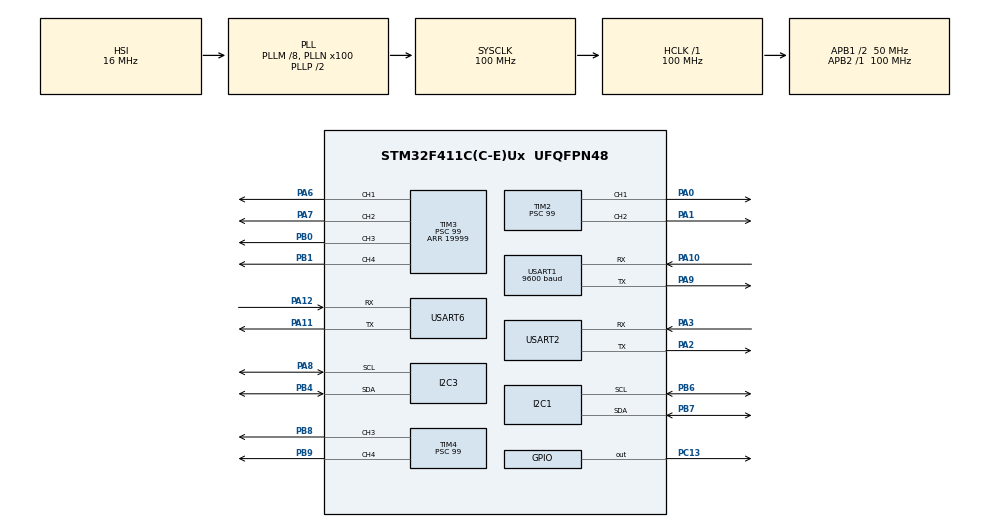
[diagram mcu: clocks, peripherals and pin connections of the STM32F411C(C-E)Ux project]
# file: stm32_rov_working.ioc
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Dma.I2C1_RX.2.Direction=DMA_PERIPH_TO_MEMORY
Dma.I2C1_RX.2.FIFOMode=DMA_FIFOMODE_DISABLE
Dma.I2C1_RX.2.Instance=DMA1_Stream0
Dma.I2C1_RX.2.MemDataAlignment=DMA_MDATAALIGN_BYTE
Dma.I2C1_RX.2.MemInc=DMA_MINC_ENABLE
Dma.I2C1_RX.2.Mode=DMA_NORMAL
Dma.I2C1_RX.2.PeriphDataAlignment=DMA_PDATAALIGN_BYTE
Dma.I2C1_RX.2.PeriphInc=DMA_PINC_DISABLE
Dma.I2C1_RX.2.Priority=DMA_PRIORITY_MEDIUM
Dma.I2C1_TX.3.Direction=DMA_MEMORY_TO_PERIPH
Dma.I2C1_TX.3.FIFOMode=DMA_FIFOMODE_DISABLE
Dma.I2C1_TX.3.Instance=DMA1_Stream1
Dma.I2C1_TX.3.MemDataAlignment=DMA_MDATAALIGN_BYTE
Dma.I2C1_TX.3.MemInc=DMA_MINC_ENABLE
Dma.I2C1_TX.3.Mode=DMA_NORMAL
Dma.I2C1_TX.3.PeriphDataAlignment=DMA_PDATAALIGN_BYTE
Dma.I2C1_TX.3.PeriphInc=DMA_PINC_DISABLE
Dma.I2C1_TX.3.Priority=DMA_PRIORITY_MEDIUM
Dma.I2C3_RX.0.Direction=DMA_PERIPH_TO_MEMORY
Dma.I2C3_RX.0.FIFOMode=DMA_FIFOMODE_DISABLE
Dma.I2C3_RX.0.Instance=DMA1_Stream2
Dma.I2C3_RX.0.MemDataAlignment=DMA_MDATAALIGN_BYTE
Dma.I2C3_RX.0.MemInc=DMA_MINC_ENABLE
Dma.I2C3_RX.0.Mode=DMA_NORMAL
Dma.I2C3_RX.0.PeriphDataAlignment=DMA_PDATAALIGN_BYTE
Dma.I2C3_RX.0.PeriphInc=DMA_PINC_DISABLE
Dma.I2C3_RX.0.Priority=DMA_PRIORITY_MEDIUM
Dma.I2C3_TX.1.Direction=DMA_MEMORY_TO_PERIPH
Dma.I2C3_TX.1.FIFOMode=DMA_FIFOMODE_DISABLE
Dma.I2C3_TX.1.Instance=DMA1_Stream4
Dma.I2C3_TX.1.MemDataAlignment=DMA_MDATAALIGN_BYTE
Dma.I2C3_TX.1.MemInc=DMA_MINC_ENABLE
Dma.I2C3_TX.1.Mode=DMA_NORMAL
Dma.I2C3_TX.1.PeriphDataAlignment=DMA_PDATAALIGN_BYTE
Dma.I2C3_TX.1.PeriphInc=DMA_PINC_DISABLE
Dma.I2C3_TX.1.Priority=DMA_PRIORITY_MEDIUM
Dma.Request0=I2C3_RX
Dma.Request1=I2C3_TX
Dma.Request2=I2C1_RX
Dma.Request3=I2C1_TX
FREERTOS.Tasks01=ledTask,8,128,StartLedTask,Default,NULL,Dynamic,NULL,NULL;uartTask,24,256,StartUartTask,Default,NULL,Dynamic,NULL,NULL
Mcu.Family=STM32F4
Mcu.Name=STM32F411C(C-E)Ux
Mcu.Package=UFQFPN48
NVIC.DMA1_Stream0_IRQn=true\:5\:0\:false\:false\:true\:true\:false\:true\:true
NVIC.DMA1_Stream1_IRQn=true\:5\:0\:false\:false\:true\:true\:false\:true\:true
NVIC.DMA1_Stream2_IRQn=true\:3\:0\:true\:false\:true\:true\:false\:true\:true
NVIC.DMA1_Stream4_IRQn=true\:4\:0\:true\:false\:true\:true\:false\:true\:true
NVIC.I2C1_ER_IRQn=true\:5\:0\:false\:false\:true\:true\:true\:true\:true
NVIC.I2C1_EV_IRQn=true\:5\:0\:false\:false\:true\:true\:true\:true\:true
NVIC.I2C3_ER_IRQn=true\:5\:0\:false\:false\:true\:true\:true\:true\:true
NVIC.I2C3_EV_IRQn=true\:5\:0\:false\:false\:true\:true\:true\:true\:true
NVIC.PriorityGroup=NVIC_PRIORITYGROUP_4
NVIC.TIM5_IRQn=true\:15\:0\:false\:false\:true\:false\:false\:true\:true
NVIC.TimeBase=TIM5_IRQn
NVIC.TimeBaseIP=TIM5
NVIC.USART1_IRQn=true\:5\:0\:false\:false\:true\:true\:true\:true\:true
NVIC.USART2_IRQn=true\:5\:0\:true\:false\:true\:true\:true\:true\:true
NVIC.USART6_IRQn=true\:5\:0\:true\:false\:true\:true\:true\:true\:true
PA0-WKUP.Signal=S_TIM2_CH1_ETR
PA1.Signal=S_TIM2_CH2
PA10.Mode=Asynchronous
PA10.Signal=USART1_RX
PA11.Mode=Asynchronous
PA11.Signal=USART6_TX
PA12.Mode=Asynchronous
PA12.Signal=USART6_RX
PA13.Mode=Serial_Wire
PA13.Signal=SYS_JTMS-SWDIO
PA14.Mode=Serial_Wire
PA14.Signal=SYS_JTCK-SWCLK
PA2.Mode=Asynchronous
PA2.Signal=USART2_TX
PA3.Mode=Asynchronous
PA3.Signal=USART2_RX
PA6.Signal=S_TIM3_CH1
PA7.Signal=S_TIM3_CH2
PA8.GPIO_Pu=GPIO_PULLUP
PA8.Mode=I2C
PA8.Signal=I2C3_SCL
PA9.Mode=Asynchronous
PA9.Signal=USART1_TX
PB0.Signal=S_TIM3_CH3
PB1.Signal=S_TIM3_CH4
PB4.GPIO_Pu=GPIO_PULLUP
PB4.Mode=I2C
PB4.Signal=I2C3_SDA
PB6.Mode=I2C
PB6.Signal=I2C1_SCL
PB7.Mode=I2C
PB7.Signal=I2C1_SDA
PB8.Signal=S_TIM4_CH3
PB9.Signal=S_TIM4_CH4
PC13-ANTI_TAMP.Signal=GPIO_Output
PH0\ -\ OSC_IN.Mode=HSE-External-Oscillator
PH0\ -\ OSC_IN.Signal=RCC_OSC_IN
PH1\ -\ OSC_OUT.Mode=HSE-External-Oscillator
PH1\ -\ OSC_OUT.Signal=RCC_OSC_OUT
ProjectManager.HeapSize=0x200
ProjectManager.StackSize=0x400
ProjectManager.TargetToolchain=STM32CubeIDE
RCC.48MHZClocksFreq_Value=28571428.57142857
RCC.AHBFreq_Value=100000000
RCC.APB1CLKDivider=RCC_HCLK_DIV2
RCC.APB1Freq_Value=50000000
RCC.APB1TimFreq_Value=100000000
RCC.APB2Freq_Value=100000000
RCC.APB2TimFreq_Value=100000000
RCC.CortexFreq_Value=100000000
RCC.HCLKFreq_Value=100000000
RCC.HSE_VALUE=25000000
RCC.HSI_VALUE=16000000
RCC.LSE_VALUE=32768
RCC.PLLM=8
RCC.PLLN=100
RCC.PLLQ=7
RCC.SYSCLKFreq_VALUE=100000000
RCC.SYSCLKSource=RCC_SYSCLKSOURCE_PLLCLK
RCC.VCOOutputFreq_Value=200000000
SH.S_TIM2_CH1_ETR.0=TIM2_CH1,PWM Generation1 CH1
SH.S_TIM2_CH2.0=TIM2_CH2,PWM Generation2 CH2
SH.S_TIM3_CH1.0=TIM3_CH1,PWM Generation1 CH1
SH.S_TIM3_CH2.0=TIM3_CH2,PWM Generation2 CH2
SH.S_TIM3_CH3.0=TIM3_CH3,PWM Generation3 CH3
SH.S_TIM3_CH4.0=TIM3_CH4,PWM Generation4 CH4
SH.S_TIM4_CH3.0=TIM4_CH3,PWM Generation3 CH3
SH.S_TIM4_CH4.0=TIM4_CH4,PWM Generation4 CH4
TIM2.AutoReloadPreload=TIM_AUTORELOAD_PRELOAD_ENABLE
TIM2.Channel-PWM\ Generation1\ CH1=TIM_CHANNEL_1
TIM2.Channel-PWM\ Generation2\ CH2=TIM_CHANNEL_2
TIM2.Period=19999
TIM2.Prescaler=99
TIM3.AutoReloadPreload=TIM_AUTORELOAD_PRELOAD_ENABLE
TIM3.Channel-PWM\ Generation1\ CH1=TIM_CHANNEL_1
TIM3.Channel-PWM\ Generation2\ CH2=TIM_CHANNEL_2
TIM3.Channel-PWM\ Generation3\ CH3=TIM_CHANNEL_3
TIM3.Channel-PWM\ Generation4\ CH4=TIM_CHANNEL_4
TIM3.Period=19999
TIM3.Prescaler=99
TIM4.AutoReloadPreload=TIM_AUTORELOAD_PRELOAD_ENABLE
TIM4.Channel-PWM\ Generation3\ CH3=TIM_CHANNEL_3
TIM4.Channel-PWM\ Generation4\ CH4=TIM_CHANNEL_4
TIM4.Period=19999
TIM4.Prescaler=99
USART1.BaudRate=9600
USART1.Parity=PARITY_EVEN
USART1.VirtualMode=VM_ASYNC
USART1.WordLength=WORDLENGTH_9B
USART2.VirtualMode=VM_ASYNC
USART6.VirtualMode=VM_ASYNC
VP_FREERTOS_VS_CMSIS_V2.Mode=CMSIS_V2
VP_SYS_VS_tim5.Mode=TIM5
VP_TIM2_VS_ClockSourceINT.Mode=Internal
VP_TIM3_VS_ClockSourceINT.Mode=Internal
VP_TIM4_VS_ClockSourceINT.Mode=Internal
board=custom

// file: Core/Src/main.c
/* USER CODE BEGIN Header */
/**
  ******************************************************************************
  * @file           : main.c
  * @brief          : Main program body
  ******************************************************************************
  * @attention
  *
  * Copyright (c) 2026 STMicroelectronics.
  * All rights reserved.
  *
  * This software is licensed under terms that can be found in the LICENSE file
  * in the root directory of this software component.
  * If no LICENSE file comes with this software, it is provided AS-IS.
  *
  ******************************************************************************
  */
/* USER CODE END Header */
#include "main.h"
#include "cmsis_os.h"
#include "dma.h"
#include "i2c.h"
#include "tim.h"
#include "usart.h"
#include "gpio.h"

/* USER CODE BEGIN Includes */
#include "app_mode.h"
#include "ms5837_dma.h"
#include "PID.h"
#include "mpu6050.h"
#include <string.h>

/* USER CODE END Includes */

/* USER CODE BEGIN PTD */
MS5837_t depth_sensor;            // Sensor instance
PID_t pid_depth;
PID_t pid_pitch;
PID_t pid_roll;
MPU6050_t mpu6050;                // MPU6050 IMU instance

/* USER CODE END PTD */

/* USER CODE BEGIN PD */

/* Task 1 bench mode: no sensors, ESC PWM, or ROV control are started. */
#define COMM_TEST_MODE  1

// ---- VERTICAL MOTORS (depth control) ----
//   V_FL = Front Left  = TIM4 CH3 = PB8
//   V_FR = Front Right = TIM4 CH4 = PB9
//   V_RL = Rear Left   = TIM2 CH1 = PA0
//   V_RR = Rear Right  = TIM3 CH4 = PB1
#define MOTOR_V_FL  TIM_CHANNEL_3   // htim4 CH3, PB8
#define MOTOR_V_FR  TIM_CHANNEL_4   // htim4 CH4, PB9
#define MOTOR_V_RL  TIM_CHANNEL_1   // htim2 CH1, PA0
#define MOTOR_V_RR  TIM_CHANNEL_4   // htim3 CH4, PB1

// ---- HORIZONTAL MOTORS ----
//   O_FL = Front Left  = TIM3 CH1 = PA6
//   O_FR = Front Right = TIM2 CH2 = PA1
//   O_RL = Rear Left   = TIM3 CH2 = PA7
//   O_RR = Rear Right  = TIM3 CH3 = PB0
#define MOTOR_O_FL  TIM_CHANNEL_1   // htim3 CH1, PA6
#define MOTOR_O_FR  TIM_CHANNEL_2   // htim2 CH2, PA1
#define MOTOR_O_RL  TIM_CHANNEL_2   // htim3 CH2, PA7
#define MOTOR_O_RR  TIM_CHANNEL_3   // htim3 CH3, PB0

/* USER CODE END PD */

/* USER CODE BEGIN PV */
float pressure, temp, depth;
float err_depth, out_depth, err_pitch , out_pitch, err_roll, out_roll;
int time = 0;
float target_depth = 0.1f;
float current_depth = 0.0f;
//float target_pitch = 4.7f;   // target pitch angle in degrees (0 = level)
//float target_roll = -2.3f;      // target roll angle in degrees (0 = level)

// --- Horizontal (omnidirectional) movement ---
// forward_input: -500 to +500  (positive = forward, negative = backward)
//int forward_input = 150;

// --- Depth stabilization gate for horizontal motors ---
// Horizontal thrust is DISABLED until depth stabilizes.
// Depth must stay within DEPTH_STABLE_TOL of target for
// DEPTH_STABLE_COUNT consecutive loop iterations.
#define DEPTH_STABLE_TOL    0.05f   // metres – how close is "stable"
#define DEPTH_STABLE_COUNT  50      // iterations (~1 s at 50 Hz loop)
int  stable_counter = 0;            // consecutive-in-range counter
int  depth_stable   = 0;            // 1 = stable, horizontal enabled
/* USER CODE END PV */

void SystemClock_Config(void);
void MX_FREERTOS_Init(void);
/* USER CODE BEGIN PFP */

void CommTest_UART_RxCpltCallback(void);
void CommTest_UART_TxCpltCallback(void);

/* USER CODE END PFP */

/* USER CODE BEGIN 0 */

int system_armed = 0;      // Safety Flag

/* HC-05 update command receiver. USART1 is PA9 (TX) / PA10 (RX). */
static uint8_t update_rx_byte;
static char update_command[16];
static uint8_t update_command_index;

/* Stop every ESC signal before handing control to the STM32 ROM bootloader. */
void ROV_ForceNeutralOutputs(void)
{
    system_armed = 0;

    __HAL_TIM_SET_COMPARE(&htim2, TIM_CHANNEL_1, 1500);
    __HAL_TIM_SET_COMPARE(&htim2, TIM_CHANNEL_2, 1500);
    __HAL_TIM_SET_COMPARE(&htim3, TIM_CHANNEL_1, 1500);
    __HAL_TIM_SET_COMPARE(&htim3, TIM_CHANNEL_2, 1500);
    __HAL_TIM_SET_COMPARE(&htim3, TIM_CHANNEL_3, 1500);
    __HAL_TIM_SET_COMPARE(&htim3, TIM_CHANNEL_4, 1500);
    __HAL_TIM_SET_COMPARE(&htim4, TIM_CHANNEL_3, 1500);
    __HAL_TIM_SET_COMPARE(&htim4, TIM_CHANNEL_4, 1500);
}

static void ROV_StopMotors(void)
{
    GPIO_InitTypeDef gpio = {0};

    ROV_ForceNeutralOutputs();

    HAL_TIM_PWM_Stop(&htim2, TIM_CHANNEL_1);
    HAL_TIM_PWM_Stop(&htim2, TIM_CHANNEL_2);
    HAL_TIM_PWM_Stop(&htim3, TIM_CHANNEL_1);
    HAL_TIM_PWM_Stop(&htim3, TIM_CHANNEL_2);
    HAL_TIM_PWM_Stop(&htim3, TIM_CHANNEL_3);
    HAL_TIM_PWM_Stop(&htim3, TIM_CHANNEL_4);
    HAL_TIM_PWM_Stop(&htim4, TIM_CHANNEL_3);
    HAL_TIM_PWM_Stop(&htim4, TIM_CHANNEL_4);

    /* Sensor-only safety lock: ESC signal pins are ordinary low outputs,
       not timer alternate-function outputs. */
    HAL_GPIO_WritePin(GPIOA,
                      GPIO_PIN_0 | GPIO_PIN_1 | GPIO_PIN_6 | GPIO_PIN_7,
                      GPIO_PIN_RESET);
    HAL_GPIO_WritePin(GPIOB,
                      GPIO_PIN_0 | GPIO_PIN_1 | GPIO_PIN_8 | GPIO_PIN_9,
                      GPIO_PIN_RESET);

    gpio.Mode = GPIO_MODE_OUTPUT_PP;
    gpio.Pull = GPIO_PULLDOWN;
    gpio.Speed = GPIO_SPEED_FREQ_LOW;

    gpio.Pin = GPIO_PIN_0 | GPIO_PIN_1 | GPIO_PIN_6 | GPIO_PIN_7;
    HAL_GPIO_Init(GPIOA, &gpio);

    gpio.Pin = GPIO_PIN_0 | GPIO_PIN_1 | GPIO_PIN_8 | GPIO_PIN_9;
    HAL_GPIO_Init(GPIOB, &gpio);
}

/* Jump to the factory STM32 USART bootloader at system-memory address. */
static void JumpToSystemBootloader(void)
{
    const uint32_t bootloader_base = 0x1FFF0000UL; /* STM32F411 system memory */
    uint32_t boot_msp;
    uint32_t boot_reset_handler;

    ROV_StopMotors();
    HAL_UART_DeInit(&huart1);

    /* The watchdog returns to the ROV firmware if a flashing session aborts. */
    IWDG->KR  = 0xCCCC;
    IWDG->KR  = 0x5555;
    IWDG->PR  = 0x03;
    IWDG->RLR = 0xAA0;
    IWDG->KR  = 0xAAAA;

    SysTick->CTRL = 0;
    SysTick->LOAD = 0;
    SysTick->VAL  = 0;

    RCC->APB2RSTR |= RCC_APB2RSTR_USART1RST;
    RCC->APB2RSTR &= ~RCC_APB2RSTR_USART1RST;

    RCC->CR |= RCC_CR_HSION;
    while ((RCC->CR & RCC_CR_HSIRDY) == 0) { }
    RCC->CFGR &= ~RCC_CFGR_SW;
    while ((RCC->CFGR & RCC_CFGR_SWS_Msk) != 0) { }
    RCC->CR &= ~(RCC_CR_PLLON | RCC_CR_HSEON);
    RCC->CFGR = 0;

    __disable_irq();
    for (uint32_t i = 0; i < 8; i++) {
        NVIC->ICER[i] = 0xFFFFFFFFUL;
        NVIC->ICPR[i] = 0xFFFFFFFFUL;
    }

    for (volatile uint32_t i = 0; i < 16000; i++) { }

    boot_msp = *(volatile uint32_t *)bootloader_base;
    boot_reset_handler = *(volatile uint32_t *)(bootloader_base + 4U);
    SCB->VTOR = bootloader_base;
    __DSB();
    __ISB();
    __set_MSP(boot_msp);
    ((void (*)(void))boot_reset_handler)();

    while (1) { }
}

void Set_Motor_PWM(TIM_HandleTypeDef *htim, uint32_t channel, int pwm) {
    __HAL_TIM_SET_COMPARE(htim, channel, pwm);
}
/* USER CODE END 0 */

int main(void)
{

  /* MCU Configuration--------------------------------------------------------*/

  /* Reset of all peripherals, Initializes the Flash interface and the Systick. */
  HAL_Init();

  /* Configure the system clock */
  SystemClock_Config();

  /* Initialize all configured peripherals */
  MX_GPIO_Init();
  MX_DMA_Init();
  MX_TIM2_Init();
  MX_TIM3_Init();
  MX_TIM4_Init();
  MX_I2C3_Init();
  MX_I2C1_Init();
  MX_USART1_UART_Init();
  MX_USART2_UART_Init();
  MX_USART6_UART_Init();
  /* USER CODE BEGIN 2 */
#if (!APP_MOTOR_OUTPUTS_ENABLED) && (!APP_MOTOR_NEUTRAL_TEST)
  ROV_StopMotors();
#endif

  /* Keep this in a USER CODE section: CubeMX regeneration will not remove it. */
  if (HAL_UART_Receive_IT(&huart1, &update_rx_byte, 1) != HAL_OK)
  {
    Error_Handler();
  }
  HAL_GPIO_WritePin(GPIOC, GPIO_PIN_13, 1);
#if !COMM_TEST_MODE
  if (MS5837_Init(&depth_sensor, &hi2c3, MS5837_OSR_4096) != MS5837_OK) {
    Error_Handler();
    } // Initalize the depth sensor

    /***********************************************************************
     * !!! IMPORTANT – IMU I2C BUS SELECTION !!!
     * The IMU (MPU6050) is initialised below using hi2c1.
     * Make sure this matches the actual I2C peripheral the IMU is wired to.
     * If your IMU is on I2C2, change &hi2c1 → &hi2c2 (and declare hi2c2).
     * If your IMU is on I2C3, change &hi2c1 → &hi2c3.
//     ***********************************************************************/
//    if (MPU6050_Init(&mpu6050, &hi2c1, MPU6050_ADDR) != HAL_OK) {
//        // IMU init failed – optionally handle error
//    }

  	PIDSourceInit(&err_depth, &out_depth, &pid_depth);
  	PIDGainInit(0.02, 1.0, 1.0, 100.0, 0.2, 0.0, 0.0, 10.0, &pid_depth);
    PIDDelayInit(&pid_depth); // initialize depth PID
//
//    // Initialize pitch PID (tune gains as needed)
//    PIDSourceInit(&err_pitch, &out_pitch, &pid_pitch);
//    PIDGainInit(0.02, 1.0, 1.0, 200.0, 0.3, 0.0, 0.0, 10.0, &pid_pitch);
//    PIDDelayInit(&pid_pitch); // initialize pitch PID
//
//    PIDSourceInit(&err_roll, &out_roll, &pid_roll);
//    PIDGainInit(0.02, 1.0, 1.0, 200.0, 0.3, 0.0, 0.0, 10.0, &pid_roll);
//    PIDDelayInit(&pid_roll); // initialize roll PID

    HAL_TIM_PWM_Start(&htim2, TIM_CHANNEL_1); // PA0
//    HAL_TIM_PWM_Start(&htim2, TIM_CHANNEL_2); // PA1
//    HAL_TIM_PWM_Start(&htim3, TIM_CHANNEL_1); // PA6
//    HAL_TIM_PWM_Start(&htim3, TIM_CHANNEL_2); // PA7
//    HAL_TIM_PWM_Start(&htim3, TIM_CHANNEL_3); // PB0
    HAL_TIM_PWM_Start(&htim3, TIM_CHANNEL_4); // PB1
    HAL_TIM_PWM_Start(&htim4, TIM_CHANNEL_3); // PB0
    HAL_TIM_PWM_Start(&htim4, TIM_CHANNEL_4); // PB1
#endif

    HAL_GPIO_WritePin(GPIOC, GPIO_PIN_13, 0);

  /* USER CODE END 2 */

  /* Init scheduler */
  osKernelInitialize();  /* Call init function for freertos objects (in cmsis_os2.c) */
  MX_FREERTOS_Init();

  /* Start scheduler */
  osKernelStart();

  /* We should never get here as control is now taken by the scheduler */

  /* Infinite loop */
  while (1)
  {

    /* USER CODE BEGIN 3 */

		  // --- IMU reading (DMA-based MPU6050) ---
//		  MPU6050_ReadAll_DMA(&mpu6050);   // kick off non-blocking DMA read
//		  MPU6050_ProcessData(&mpu6050);   // process if DMA data is ready

		  static uint32_t last_time = 0;
		  	    if ((HAL_GetTick() - last_time) >= 100) {
		  	        if (MS5837_GetState(&depth_sensor) == MS5837_STATE_IDLE) {
		  	            MS5837_StartReading(&depth_sensor);
		  	            last_time = HAL_GetTick();
		  	        }
		  	    }

		  	    MS5837_Process(&depth_sensor);

		  	    if (MS5837_IsDataReady(&depth_sensor)) {
		  	         pressure = MS5837_GetPressure(&depth_sensor);
		  	         temp = MS5837_GetTemperature(&depth_sensor);
		  	         depth = MS5837_GetDepth(&depth_sensor);
		  	    	 current_depth = MS5837_GetDepth(&depth_sensor);
		  	    }
		  	  if (system_armed)
		  	  	    {

//		  	  	    	err_depth = target_depth - current_depth;
//		  	  	    	PID(&pid_depth);
		  	  	    // ============================
		  	  	    // DEPTH PID CONTROL ONLY
		  	  	    // ============================

		  	  	    // Calculate depth error
		  	  	    err_depth = target_depth - current_depth;

		  	  	    // PID calculation
		  	  	    PID(&pid_depth);

		  	  	    // Convert PID output to PWM correction
		  	  	    int u_depth = (int)(out_depth * 2);

		  	  	    // Dead zone compensation
		  	  	    if(u_depth > 0)
		  	  	    {
		  	  	        u_depth += 80;
		  	  	    }
		  	  	    else if(u_depth < 0)
		  	  	    {
		  	  	        u_depth -= 80;
		  	  	    }

		  	  	    // Limit PID output
		  	  	    if(u_depth > 300)
		  	  	        u_depth = 300;

		  	  	    if(u_depth < -300)
		  	  	        u_depth = -300;

		  	  	    int base = 1500;

		  	  	    // ============================
		  	  	    // VERTICAL MOTOR MIXING
		  	  	    // DEPTH ONLY
		  	  	    // ============================

		  	  	    int pwm_FL = base + u_depth;
		  	  	    int pwm_FR = base + u_depth;
		  	  	    int pwm_RL = base + u_depth;
		  	  	    int pwm_RR = base + u_depth;

		  	  	    // PWM safety limit
		  	  	    if(pwm_FL > 1800) pwm_FL = 1800;
		  	  	    if(pwm_FL < 1200) pwm_FL = 1200;

		  	  	    if(pwm_FR > 1800) pwm_FR = 1800;
		  	  	    if(pwm_FR < 1200) pwm_FR = 1200;

		  	  	    if(pwm_RL > 1800) pwm_RL = 1800;
		  	  	    if(pwm_RL < 1200) pwm_RL = 1200;

		  	  	    if(pwm_RR > 1800) pwm_RR = 1800;
		  	  	    if(pwm_RR < 1200) pwm_RR = 1200;

		  	  	    // Send PWM
		  	  	    __HAL_TIM_SET_COMPARE(&htim4, TIM_CHANNEL_3, pwm_FL);
		  	  	    __HAL_TIM_SET_COMPARE(&htim4, TIM_CHANNEL_4, pwm_FR);

		  	  	    __HAL_TIM_SET_COMPARE(&htim2, TIM_CHANNEL_1, pwm_RL);

		  	  	    __HAL_TIM_SET_COMPARE(&htim3, TIM_CHANNEL_4, pwm_RR);

//		  	  	    	// --- Pitch PID (uses MPU6050 pitch) ---
//		  	  	    	err_pitch = target_pitch - MPU6050_GetPitch(&mpu6050);
//		  	  	    	PID(&pid_pitch);
//
//		  	  	    	// --- Roll PID (uses MPU6050 roll) ---
//		  	  	    	err_roll = target_roll - MPU6050_GetRoll(&mpu6050);
//		  	  	    	PID(&pid_roll);

//		  	  		      int base = 1500;
//
//		  	  		      // --- Depth PID output ---
//		  	  		      int u_depth = 200;
//
//		  	  		      //   Dead zone compensation
//		  	  		      if (u_depth > 0) u_depth += 100;
//		  	  		      if (u_depth < 0) u_depth -= 100;
//		  	  		      // Limit
//		  	  		      if (u_depth > 300) u_depth = 300;
//		  	  		      if (u_depth < -300) u_depth = -300;

//		  	  		      // --- Pitch PID output ---
//		  	  		      int u_pitch = (int)(out_pitch * 2);
//
//		  	  		      // Pitch dead zone compensation
//		  	  		      if (u_pitch > 0) u_pitch += 50;
//		  	  		      if (u_pitch < 0) u_pitch -= 50;
//		  	  		      // Pitch limit
//		  	  		      if (u_pitch > 200) u_pitch = 200;
//		  	  		      if (u_pitch < -200) u_pitch = -200;
//
//                           // ----- roll PID output -----
//                          int u_roll = (int)(out_roll * 2);
//                          // Roll dead zone compensation
//                          if (u_roll > 0) u_roll += 50;
//                          if (u_roll < 0) u_roll -= 50;
//                               // Roll limit
//                          if (u_roll > 200) u_roll = 200;
//                          if (u_roll < -200) u_roll = -200;

		  	  		      /***********************************************************************
		  	  		       * VERTICAL MOTOR MIXING: depth + pitch + roll
		  	  		       *
		  	  		       *   u_depth : common-mode (all motors together for heave)
		  	  		       *   u_pitch : differential  (front vs rear for pitch torque)
		  	  		       *    u_roll  : differential  (left vs right for roll torque)
		  	  		       *   Positive pitch error = nose up  → push front down, rear up
		  	  		       *     Front motors: subtract u_pitch (more thrust downward)
		  	  		       *     Rear  motors: add u_pitch      (less thrust downward)
		  	  		       *
		  	  		       * !!! FIRST TEST: If pitch correction is reversed, swap the
		  	  		       *     +/- signs on u_pitch below. !!!
		  	  		       ***********************************************************************/
		  	  		      // FR (Front Right)

//		  	  		      int pwm_FR = base + u_depth ;
//
//		  	  		      // FL (Front Left)
//		  	  		      int pwm_FL = base + u_depth ;
//
//		  	  		      // RL (Rear Left)
//		  	  		      int pwm_RL = base - u_depth ;
//
//		  	  		      // RR (Rear Right)
//		  	  		      int pwm_RR = base - u_depth ;
//		  	  	//
//		  	  	//	      // --- E. SAFETY CLAMP ---
//		  	  		      if(pwm_FL > 1900) pwm_FL = 1900;
//		  	  		      if(pwm_FL < 1100) pwm_FL = 1100;
//		  	  		      if(pwm_FR > 1900) pwm_FR = 1900;
//		  	  		      if(pwm_FR < 1100) pwm_FR = 1100;
//		  	  		      if(pwm_RL > 1900) pwm_RL = 1900;
//		  	  		      if(pwm_RL < 1100) pwm_RL = 1100;
//		  	  		      if(pwm_RR > 1900) pwm_RR = 1900;
//		  	  		      if(pwm_RR < 1100) pwm_RR = 1100;
//		  	              __HAL_TIM_SET_COMPARE(&htim4, TIM_CHANNEL_3, pwm_FL);
//		  	              __HAL_TIM_SET_COMPARE(&htim4, TIM_CHANNEL_4, pwm_FR);
//	     //	  	          __HAL_TIM_SET_COMPARE(&htim3, TIM_CHANNEL_2, pwm_RL);
//	  //	  	          __HAL_TIM_SET_COMPARE(&htim4, TIM_CHANNEL_4,pwm_RR );
//		  	              __HAL_TIM_SET_COMPARE(&htim2, TIM_CHANNEL_1, pwm_RL);
//		  	              __HAL_TIM_SET_COMPARE(&htim3, TIM_CHANNEL_4, pwm_RR);

		  	        // ===== HORIZONTAL MOTORS (forward/backward) =====
		  	        	  	  		      // Only enabled after depth has stabilized
		  	        	  	  		      /***********************************************************************
		  	        	  	  		       * !!! IMPORTANT – VERIFY HORIZONTAL MOTOR DIRECTIONS !!!
		  	        	  	  		       * The +/- signs below assume a standard 45° X-configuration:
		  	        	  	  		       *   O_FL & O_RR spin one way  → "+u_fwd" (normal)
		  	        	  	  		       *   O_FR & O_RL spin opposite → "-u_fwd" (flipped)
		  	        	  	  		       *
		  	        	  	  		       * On FIRST TEST: set forward_input = +200 and observe the ROV.
		  	        	  	  		       *   - If it moves BACKWARD instead of forward, swap ALL signs
		  	        	  	  		       *     (i.e. change +u_fwd to -u_fwd and vice-versa).
		  	        	  	  		       *   - If it spins/yaws instead of translating, swap signs on
		  	        	  	  		       *     only the diagonal pair that is wrong.
		  	        	  	  		       ***********************************************************************/
//		  	        	  	  		      if ((err_depth < 0.05f) && (err_depth > -0.05f)) {
//		  	        	  	  		          int u_fwd = forward_input; // range: -500 to +500
//
//		  	        	  	  		          // O_FL (htim3 CH1) - normal direction
//		  	        	  	  		          int pwm_O_FL = base + u_fwd;
//		  	        	  	  		          // O_FR (htim2 CH2) - flipped direction
//		  	        	  	  		          int pwm_O_FR = base + u_fwd;
//		  	        	  	  		          // O_RL (htim3 CH3) - flipped direction
//		  	        	  	  		          int pwm_O_RL = base - u_fwd;
//		  	        	  	  		          // O_RR (htim3 CH2) - normal direction
//		  	        	  	  		          int pwm_O_RR = base + u_fwd;
//
//		  	        	  	  		          // --- HORIZONTAL SAFETY CLAMP ---
//		  	        	  	  		          if(pwm_O_FL > 1900) pwm_O_FL = 1700;
//		  	        	  	  		          if(pwm_O_FL < 1100) pwm_O_FL = 1200;
//		  	        	  	  		          if(pwm_O_FR > 1900) pwm_O_FR = 1700;
//	  	         	  	  		              if(pwm_O_FR < 1100) pwm_O_FR = 1200;
//		  	        	  	  		          if(pwm_O_RL > 1900) pwm_O_RL = 1700;
//		  	        	  	  		          if(pwm_O_RL < 1100) pwm_O_RL = 1200;
//		  	        	  	  		          if(pwm_O_RR > 1900) pwm_O_RR = 1700;
//		  	        	  	  		          if(pwm_O_RR < 1100) pwm_O_RR = 1200;
//
//		  	        	  	  		          // --- WRITE HORIZONTAL MOTORS ---
//		  	        	  	  		          __HAL_TIM_SET_COMPARE(&htim3, TIM_CHANNEL_1, pwm_O_FL);  // O_FL
//		  	        	  	  		          __HAL_TIM_SET_COMPARE(&htim2, TIM_CHANNEL_2, pwm_O_FR);  // O_FR
//		  	        	  	  		          __HAL_TIM_SET_COMPARE(&htim3, TIM_CHANNEL_3, pwm_O_RL);  // O_RL
//		  	        	  	  		          __HAL_TIM_SET_COMPARE(&htim3, TIM_CHANNEL_2, pwm_O_RR);  // O_RR
//	 	        	  	  		              }
//		  	        	  	  		      else {
//		//  	        	  	  		          else {
//	//	  	        	  	  		          // Depth NOT stable yet → hold horizontal motors at neutral
//		  	        	  	  		          __HAL_TIM_SET_COMPARE(&htim3, TIM_CHANNEL_1, 1500);  // O_FL
//		  	        	  	  		          __HAL_TIM_SET_COMPARE(&htim2, TIM_CHANNEL_2, 1500);  // O_FR
//		  	        	  	  		          __HAL_TIM_SET_COMPARE(&htim3, TIM_CHANNEL_3, 1500);  // O_RL
//		  	        	  	  		          __HAL_TIM_SET_COMPARE(&htim3, TIM_CHANNEL_2, 1500);  // O_RR
//		  	        	  	  		      }
	//

		  	  	    }
		  	  	    else{

		  	  	    	pid_depth.s_delay = 0;
		  	  	    	out_depth = 0;
		  	  	    for (int i = 0; i <= 2; i++){
		  	  	  	__HAL_TIM_SET_COMPARE(&htim4, TIM_CHANNEL_4, 1500);
		  	  	  	__HAL_TIM_SET_COMPARE(&htim4, TIM_CHANNEL_3, 1500);
		  	  	  	__HAL_TIM_SET_COMPARE(&htim3, TIM_CHANNEL_2, 1500);
		  	  	  	__HAL_TIM_SET_COMPARE(&htim3, TIM_CHANNEL_3, 1500);
		  	    	__HAL_TIM_SET_COMPARE(&htim2, TIM_CHANNEL_1, 1500);
		  	    	__HAL_TIM_SET_COMPARE(&htim2, TIM_CHANNEL_2, 1500);
		  	    	__HAL_TIM_SET_COMPARE(&htim3, TIM_CHANNEL_1, 1500);
		  	    	__HAL_TIM_SET_COMPARE(&htim3, TIM_CHANNEL_4, 1500);

		  	  	  	HAL_Delay(2000);

		  	  	  	__HAL_TIM_SET_COMPARE(&htim4, TIM_CHANNEL_4, 1700);
		  	  	  	__HAL_TIM_SET_COMPARE(&htim4, TIM_CHANNEL_3, 1700);
		  	  	  	__HAL_TIM_SET_COMPARE(&htim3, TIM_CHANNEL_2, 1700);
		  	  	  	__HAL_TIM_SET_COMPARE(&htim3, TIM_CHANNEL_3, 1700);
		  	    	__HAL_TIM_SET_COMPARE(&htim2, TIM_CHANNEL_1, 1700);
		  	    	__HAL_TIM_SET_COMPARE(&htim2, TIM_CHANNEL_2, 1700);
	     	    	__HAL_TIM_SET_COMPARE(&htim3, TIM_CHANNEL_1, 1700);
	    	    	__HAL_TIM_SET_COMPARE(&htim3, TIM_CHANNEL_4, 1700);
	    	    	HAL_Delay(2000);
	                }
		  		  	  	system_armed = 1;
//		  		  	__HAL_TIM_SET_COMPARE(&htim2, TIM_CHANNEL_1, 1500);  // O_FL
//		  		    __HAL_TIM_SET_COMPARE(&htim3, TIM_CHANNEL_4, 1500);  // O_FR
//		  		  	__HAL_TIM_SET_COMPARE(&htim3, TIM_CHANNEL_2, 1500);  // O_RL
//		  		  	__HAL_TIM_SET_COMPARE(&htim3, TIM_CHANNEL_3, 1500);  // O_RR
		  	  	    }
    /* USER CODE BEGIN 3 */

  }
  /* USER CODE END 3 */
}

void SystemClock_Config(void)
{
  RCC_OscInitTypeDef RCC_OscInitStruct = {0};
  RCC_ClkInitTypeDef RCC_ClkInitStruct = {0};

  /** Configure the main internal regulator output voltage
  */
  __HAL_RCC_PWR_CLK_ENABLE();
  __HAL_PWR_VOLTAGESCALING_CONFIG(PWR_REGULATOR_VOLTAGE_SCALE1);

  /** Initializes the RCC Oscillators according to the specified parameters
  * in the RCC_OscInitTypeDef structure.
  */
  RCC_OscInitStruct.OscillatorType = RCC_OSCILLATORTYPE_HSI;
  RCC_OscInitStruct.HSIState = RCC_HSI_ON;
  RCC_OscInitStruct.HSICalibrationValue = RCC_HSICALIBRATION_DEFAULT;
  RCC_OscInitStruct.PLL.PLLState = RCC_PLL_ON;
  RCC_OscInitStruct.PLL.PLLSource = RCC_PLLSOURCE_HSI;
  RCC_OscInitStruct.PLL.PLLM = 8;
  RCC_OscInitStruct.PLL.PLLN = 100;
  RCC_OscInitStruct.PLL.PLLP = RCC_PLLP_DIV2;
  RCC_OscInitStruct.PLL.PLLQ = 7;
  if (HAL_RCC_OscConfig(&RCC_OscInitStruct) != HAL_OK)
  {
    Error_Handler();
  }

  /** Initializes the CPU, AHB and APB buses clocks
  */
  RCC_ClkInitStruct.ClockType = RCC_CLOCKTYPE_HCLK|RCC_CLOCKTYPE_SYSCLK
                              |RCC_CLOCKTYPE_PCLK1|RCC_CLOCKTYPE_PCLK2;
  RCC_ClkInitStruct.SYSCLKSource = RCC_SYSCLKSOURCE_PLLCLK;
  RCC_ClkInitStruct.AHBCLKDivider = RCC_SYSCLK_DIV1;
  RCC_ClkInitStruct.APB1CLKDivider = RCC_HCLK_DIV2;
  RCC_ClkInitStruct.APB2CLKDivider = RCC_HCLK_DIV1;

  if (HAL_RCC_ClockConfig(&RCC_ClkInitStruct, FLASH_LATENCY_3) != HAL_OK)
  {
    Error_Handler();
  }
}

/* USER CODE BEGIN 4 */

// DMA Rx complete callback – routes to MPU6050 driver
void HAL_I2C_MemRxCpltCallback(I2C_HandleTypeDef *hi2c)
{
    MPU6050_DMA_CompleteCallback(&mpu6050, hi2c);
}

/* Receive the ASCII command "UP" followed by Enter from STM32ProgrammerApp. */
void HAL_UART_RxCpltCallback(UART_HandleTypeDef *huart)
{
    if (huart->Instance == USART6) {
        CommTest_UART_RxCpltCallback();
        return;
    }

    if (huart->Instance != USART1) {
        return;
    }

    /* PC13 LED is active-low: toggle on every received byte for diagnosis. */
    HAL_GPIO_TogglePin(GPIOC, GPIO_PIN_13);

    if ((update_rx_byte == '\r') || (update_rx_byte == '\n')) {
        update_command[update_command_index] = '\0';
        if (strcmp(update_command, "UP") == 0) {
            HAL_GPIO_WritePin(GPIOC, GPIO_PIN_13, GPIO_PIN_SET);
            JumpToSystemBootloader();
        }
        update_command_index = 0U;
    } else if (update_command_index < (sizeof(update_command) - 1U)) {
        update_command[update_command_index++] = (char)update_rx_byte;
        update_command[update_command_index] = '\0';

        /* Accept UP immediately; an Enter key is optional. */
        if (strcmp(update_command, "UP") == 0) {
            HAL_GPIO_WritePin(GPIOC, GPIO_PIN_13, GPIO_PIN_SET);
            JumpToSystemBootloader();
        }
    } else {
        update_command_index = 0U;
    }

    (void)HAL_UART_Receive_IT(&huart1, &update_rx_byte, 1);
}

void HAL_UART_TxCpltCallback(UART_HandleTypeDef *huart)
{
    if (huart->Instance == USART6) {
        CommTest_UART_TxCpltCallback();
    }
}

/* USER CODE END 4 */

void HAL_TIM_PeriodElapsedCallback(TIM_HandleTypeDef *htim)
{
  if (htim->Instance == TIM5)
  {
    HAL_IncTick();
  }
}

void Error_Handler(void)
{
  /* USER CODE BEGIN Error_Handler_Debug */
  /* User can add his own implementation to report the HAL error return state */
  __disable_irq();
  while (MS5837_Init(&depth_sensor, &hi2c3, MS5837_OSR_4096))
  {

  }
  /* USER CODE END Error_Handler_Debug */
}

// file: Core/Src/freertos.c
/* USER CODE BEGIN Header */
/**
  ******************************************************************************
  * File Name          : freertos.c
  * Description        : Code for freertos applications
  ******************************************************************************
  * @attention
  *
  * Copyright (c) 2026 STMicroelectronics.
  * All rights reserved.
  *
  * This software is licensed under terms that can be found in the LICENSE file
  * in the root directory of this software component.
  * If no LICENSE file comes with this software, it is provided AS-IS.
  *
  ******************************************************************************
  */
/* USER CODE END Header */

#include "FreeRTOS.h"
#include "task.h"
#include "main.h"
#include "cmsis_os.h"

/* USER CODE BEGIN Includes */
#include "app_mode.h"
#include "comm_interface.h"
#include "comm_encoder.h"
#include "comm_encoder_selftest.h"
#include "comm_parser.h"
#include "comm_parser_selftest.h"
#include "i2c.h"
#include "mpu6050.h"
#include "ms5837_dma.h"
#include "movement.h"
#include "usart.h"
#include "queue.h"
#include "semphr.h"
#include <string.h>

/* USER CODE END Includes */

/* USER CODE BEGIN PTD */
typedef struct
{
  uint8_t motor_index;
  int8_t direction;
} MotorTestRequest_t;

/* USER CODE END PTD */

/* USER CODE BEGIN PD */
#define SENSOR_TASK_PERIOD_MS          10U
#define IMU_SAMPLE_PERIOD_MS           20U
#define IMU_STALE_TIMEOUT_MS          500U
#define MAG_SAMPLE_PERIOD_MS           20U
#define MAG_STALE_TIMEOUT_MS          500U
#define DEPTH_STALE_TIMEOUT_MS       1000U
#define SENSOR_FAULT_TIMEOUT_MS      2000U
#define SENSOR_RETRY_PERIOD_MS       1000U
#define DEPTH_SURFACE_SAMPLE_COUNT     20U
#define WATER_DENSITY_KG_M3          997.0f
#define STANDARD_GRAVITY_M_S2          9.80665f
#define CONTROL_SAFETY_PERIOD_MS       20U
#define COMMAND_LINK_TIMEOUT_MS       500U
#define SINGLE_MOTOR_TEST_DURATION_MS  250U

/* USER CODE END PD */

/* USER CODE BEGIN Variables */
static QueueHandle_t commUartRxQueueHandle;
static QueueHandle_t motorTestQueueHandle;
static uint8_t commUartRxByte;
static SemaphoreHandle_t commUartTxMutexHandle;
static SemaphoreHandle_t commUartTxDoneSemaphoreHandle;
static osThreadId_t telemetryTaskHandle;
static osThreadId_t sensorTaskHandle;
static osThreadId_t controlSafetyTaskHandle;
extern MPU6050_t mpu6050;
extern MS5837_t depth_sensor;
static HW290_Magnetometer_t hw290Magnetometer;
static const osThreadAttr_t telemetryTaskAttributes = {
  .name = "telemetryTask",
  .stack_size = 256U * 4U,
  .priority = (osPriority_t)osPriorityLow,
};
static const osThreadAttr_t sensorTaskAttributes = {
  .name = "sensorTask",
  .stack_size = 512U * 4U,
  .priority = (osPriority_t)osPriorityLow,
};
static const osThreadAttr_t controlSafetyTaskAttributes = {
  .name = "controlSafetyTask",
  .stack_size = 256U * 4U,
  .priority = (osPriority_t)osPriorityAboveNormal,
};

/* USER CODE END Variables */
/* Definitions for ledTask */
osThreadId_t ledTaskHandle;
const osThreadAttr_t ledTask_attributes = {
  .name = "ledTask",
  .stack_size = 128 * 4,
  .priority = (osPriority_t) osPriorityLow,
};
/* Definitions for uartTask */
osThreadId_t uartTaskHandle;
const osThreadAttr_t uartTask_attributes = {
  .name = "uartTask",
  .stack_size = 256 * 4,
  .priority = (osPriority_t) osPriorityNormal,
};

/* USER CODE BEGIN FunctionPrototypes */
static void StartTelemetryTask(void *argument);
static void StartSensorTask(void *argument);
static void StartControlSafetyTask(void *argument);
static void CommTest_UART_SendText(const uint8_t *data, uint16_t length);
static int16_t Sensor_DegreesToCentidegrees(float degrees);
static int32_t Sensor_MetresToMillimetres(float metres);
/* USER CODE END FunctionPrototypes */

void StartLedTask(void *argument);
void StartUartTask(void *argument);

void MX_FREERTOS_Init(void); /* (MISRA C 2004 rule 8.1) */

void MX_FREERTOS_Init(void) {

  /* USER CODE BEGIN RTOS_MUTEX */
  /* Protect the command and telemetry snapshots shared by RTOS tasks. */
  if (!CommInterface_Init())
  {
    Error_Handler();
  }

  /* Serialize diagnostic text and asynchronous telemetry on USART6 TX. */
  commUartTxMutexHandle = xSemaphoreCreateMutex();
  if (commUartTxMutexHandle == NULL)
  {
    Error_Handler();
  }
  /* USER CODE END RTOS_MUTEX */

  /* USER CODE BEGIN RTOS_SEMAPHORES */
  /* USART6 TX-complete interrupt wakes the telemetry task through this. */
  commUartTxDoneSemaphoreHandle = xSemaphoreCreateBinary();
  if (commUartTxDoneSemaphoreHandle == NULL)
  {
    Error_Handler();
  }
  /* USER CODE END RTOS_SEMAPHORES */

  /* USER CODE BEGIN RTOS_QUEUES */
  /* The USART6 interrupt puts received bytes here for uartTask to process. */
  commUartRxQueueHandle = xQueueCreate(128U, sizeof(uint8_t));
  motorTestQueueHandle = xQueueCreate(1U, sizeof(MotorTestRequest_t));
  if ((commUartRxQueueHandle == NULL) || (motorTestQueueHandle == NULL))
  {
    Error_Handler();
  }
  /* USER CODE END RTOS_QUEUES */

  /* Create the thread(s) */
  /* creation of ledTask */
  ledTaskHandle = osThreadNew(StartLedTask, NULL, &ledTask_attributes);

  /* creation of uartTask */
  uartTaskHandle = osThreadNew(StartUartTask, NULL, &uartTask_attributes);

  /* USER CODE BEGIN RTOS_THREADS */
  telemetryTaskHandle = osThreadNew(StartTelemetryTask, NULL,
                                    &telemetryTaskAttributes);
  if (telemetryTaskHandle == NULL)
  {
    Error_Handler();
  }

  controlSafetyTaskHandle = osThreadNew(StartControlSafetyTask, NULL,
                                        &controlSafetyTaskAttributes);
  if (controlSafetyTaskHandle == NULL)
  {
    Error_Handler();
  }

#if APP_SENSOR_TASK_ENABLED
  sensorTaskHandle = osThreadNew(StartSensorTask, NULL, &sensorTaskAttributes);
  if (sensorTaskHandle == NULL)
  {
    Error_Handler();
  }
#endif
  /* USER CODE END RTOS_THREADS */

}

void StartLedTask(void *argument)
{
  /* USER CODE BEGIN StartLedTask */
  (void)argument;

  /* PC13 is the active-low LED on the Blackpill. */
  for(;;)
  {
    HAL_GPIO_TogglePin(GPIOC, GPIO_PIN_13);
    osDelay(500U);
  }
  /* USER CODE END StartLedTask */
}

void StartUartTask(void *argument)
{
  /* USER CODE BEGIN StartUartTask */
  static const uint8_t readyMessage[] = "STM32 READY\r\n";
  static const uint8_t pongMessage[] = "PONG\r\n";
  static const uint8_t selfTestPassMessage[] = "SELFTEST PASS\r\n";
  static const uint8_t encoderTestPassMessage[] = "ENCODERTEST PASS\r\n";
  static const uint8_t mixerTestPassMessage[] = "MIXERTEST PASS\r\n";
  static const uint8_t pwmTestPassMessage[] = "PWMTEST PASS\r\n";
#if APP_SINGLE_MOTOR_TEST_ENABLED
  static const uint8_t motorTestQueuedMessage[] = "MOTORTEST QUEUED\r\n";
  static const uint8_t motorTestBusyMessage[] = "MOTORTEST BUSY\r\n";
#endif
  static const uint8_t errorMessage[] = "UNKNOWN\r\n";
  static const uint8_t commandCrcError[] = "CMD ERROR CRC\r\n";
  static const uint8_t commandVersionError[] = "CMD ERROR VERSION\r\n";
  static const uint8_t commandTypeError[] = "CMD ERROR TYPE\r\n";
  static const uint8_t commandLengthError[] = "CMD ERROR LENGTH\r\n";
  static const uint8_t commandRangeError[] = "CMD ERROR RANGE\r\n";
  static const uint8_t commandStoreError[] = "CMD ERROR STORE\r\n";
  uint8_t selfTestFailureMessage[] = "SELFTEST FAIL 0\r\n";
  uint8_t encoderTestFailureMessage[] = "ENCODERTEST FAIL 0\r\n";
  uint8_t mixerTestFailureMessage[] = "MIXERTEST FAIL 0\r\n";
  uint8_t pwmTestFailureMessage[] = "PWMTEST FAIL 0\r\n";
  uint8_t commandOkMessage[] = "CMD OK SEQ=00\r\n";
  char command[16];
  size_t commandIndex = 0U;
  uint8_t receivedByte;
  CommParser_t binaryParser;
  ControlCommand_t receivedCommand;
  CommParseResult_t parseResult;
#if APP_SINGLE_MOTOR_TEST_ENABLED
  MotorTestRequest_t motorTestRequest;
#endif

  (void)argument;

  if (commUartRxQueueHandle == NULL)
  {
    Error_Handler();
  }

  CommParser_Init(&binaryParser);

  if (HAL_UART_Receive_IT(&huart6, &commUartRxByte, 1U) != HAL_OK)
  {
    Error_Handler();
  }

  CommTest_UART_SendText(readyMessage, sizeof(readyMessage) - 1U);

  for(;;)
  {
    if (xQueueReceive(commUartRxQueueHandle, &receivedByte, portMAX_DELAY) != pdPASS)
    {
      continue;
    }

    /* Once 0xAA is seen, route all bytes to the binary packet parser until
       that frame is complete or rejected. ASCII PING/SELFTEST remain useful
       while the parser is waiting for a new binary frame. */
    if ((binaryParser.state != COMM_PARSER_WAIT_SOF_1) ||
        (receivedByte == COMM_SOF_1))
    {
      parseResult = CommParser_PushByte(&binaryParser, receivedByte,
                                        HAL_GetTick(), &receivedCommand);
      commandIndex = 0U;

      if (parseResult == COMM_PARSE_COMMAND_READY)
      {
        uint16_t knownFlags = COMM_COMMAND_ARM_REQUEST |
                              COMM_COMMAND_DEPTH_HOLD_ENABLE |
                              COMM_COMMAND_EMERGENCY_STOP;
        bool commandInRange =
            ((receivedCommand.control_flags & (uint16_t)(~knownFlags)) == 0U) &&
            (receivedCommand.surge_permille >= -1000) &&
            (receivedCommand.surge_permille <= 1000) &&
            (receivedCommand.sway_permille >= -1000) &&
            (receivedCommand.sway_permille <= 1000) &&
            (receivedCommand.heave_permille >= -1000) &&
            (receivedCommand.heave_permille <= 1000) &&
            (receivedCommand.yaw_permille >= -1000) &&
            (receivedCommand.yaw_permille <= 1000);

        if (!commandInRange)
        {
          CommTest_UART_SendText(commandRangeError,
                                 sizeof(commandRangeError) - 1U);
        }
        else if (!CommInterface_SetCommand(&receivedCommand,
                                           pdMS_TO_TICKS(10U)))
        {
          CommTest_UART_SendText(commandStoreError,
                                 sizeof(commandStoreError) - 1U);
        }
        else
        {
          static const char hexDigits[] = "0123456789ABCDEF";
          commandOkMessage[11] =
              (uint8_t)hexDigits[(receivedCommand.sequence >> 4) & 0x0FU];
          commandOkMessage[12] =
              (uint8_t)hexDigits[receivedCommand.sequence & 0x0FU];
          CommTest_UART_SendText(commandOkMessage,
                                 sizeof(commandOkMessage) - 1U);
        }
      }
      else if (parseResult == COMM_PARSE_ERROR_CRC)
      {
        CommTest_UART_SendText(commandCrcError,
                               sizeof(commandCrcError) - 1U);
      }
      else if (parseResult == COMM_PARSE_ERROR_VERSION)
      {
        CommTest_UART_SendText(commandVersionError,
                               sizeof(commandVersionError) - 1U);
      }
      else if (parseResult == COMM_PARSE_ERROR_TYPE)
      {
        CommTest_UART_SendText(commandTypeError,
                               sizeof(commandTypeError) - 1U);
      }
      else if (parseResult == COMM_PARSE_ERROR_LENGTH)
      {
        CommTest_UART_SendText(commandLengthError,
                               sizeof(commandLengthError) - 1U);
      }

      continue;
    }

    if (receivedByte == '\r')
    {
      continue;
    }

    if (receivedByte == '\n')
    {
      command[commandIndex] = '\0';

      if (strcmp(command, "PING") == 0)
      {
        CommTest_UART_SendText(pongMessage, sizeof(pongMessage) - 1U);
      }
      else if (strcmp(command, "SELFTEST") == 0)
      {
        uint8_t failedTest = CommParser_RunSelfTest();

        if (failedTest == 0U)
        {
          CommTest_UART_SendText(selfTestPassMessage,
                                 sizeof(selfTestPassMessage) - 1U);
        }
        else
        {
          selfTestFailureMessage[14] = (uint8_t)('0' + failedTest);
          CommTest_UART_SendText(selfTestFailureMessage,
                                 sizeof(selfTestFailureMessage) - 1U);
        }
      }
      else if (strcmp(command, "ENCODERTEST") == 0)
      {
        uint8_t failedTest = CommEncoder_RunSelfTest();

        if (failedTest == 0U)
        {
          CommTest_UART_SendText(encoderTestPassMessage,
                                 sizeof(encoderTestPassMessage) - 1U);
        }
        else
        {
          encoderTestFailureMessage[17] = (uint8_t)('0' + failedTest);
          CommTest_UART_SendText(encoderTestFailureMessage,
                                 sizeof(encoderTestFailureMessage) - 1U);
        }
      }
      else if (strcmp(command, "MIXERTEST") == 0)
      {
        uint8_t failedTest = Movement_RunSelfTest();

        if (failedTest == 0U)
        {
          CommTest_UART_SendText(mixerTestPassMessage,
                                 sizeof(mixerTestPassMessage) - 1U);
        }
        else
        {
          mixerTestFailureMessage[15] = (uint8_t)('0' + failedTest);
          CommTest_UART_SendText(mixerTestFailureMessage,
                                 sizeof(mixerTestFailureMessage) - 1U);
        }
      }
      else if (strcmp(command, "PWMTEST") == 0)
      {
        uint8_t failedTest = Movement_RunPwmNeutralTest();

        if (failedTest == 0U)
        {
          CommTest_UART_SendText(pwmTestPassMessage,
                                 sizeof(pwmTestPassMessage) - 1U);
        }
        else
        {
          pwmTestFailureMessage[13] = (uint8_t)('0' + failedTest);
          CommTest_UART_SendText(pwmTestFailureMessage,
                                 sizeof(pwmTestFailureMessage) - 1U);
        }
      }
#if APP_SINGLE_MOTOR_TEST_ENABLED
      else if ((commandIndex == 3U) && (command[0] == 'M') &&
               (command[1] >= '1') && (command[1] <= '8') &&
               ((command[2] == '+') || (command[2] == '-')))
      {
        motorTestRequest.motor_index = (uint8_t)(command[1] - '1');
        motorTestRequest.direction = (command[2] == '+') ? 1 : -1;

        if (xQueueSend(motorTestQueueHandle, &motorTestRequest, 0U) == pdPASS)
        {
          CommTest_UART_SendText(motorTestQueuedMessage,
                                 sizeof(motorTestQueuedMessage) - 1U);
        }
        else
        {
          CommTest_UART_SendText(motorTestBusyMessage,
                                 sizeof(motorTestBusyMessage) - 1U);
        }
      }
#endif
      else if (commandIndex > 0U)
      {
        CommTest_UART_SendText(errorMessage, sizeof(errorMessage) - 1U);
      }

      commandIndex = 0U;
    }
    else if (commandIndex < (sizeof(command) - 1U))
    {
      command[commandIndex++] = (char)receivedByte;
    }
    else
    {
      /* Discard a line that is longer than the command buffer. */
      commandIndex = 0U;
    }
  }
  /* USER CODE END StartUartTask */
}

/* USER CODE BEGIN Application */

static void CommTest_UART_SendText(const uint8_t *data, uint16_t length)
{
  if ((data == NULL) || (length == 0U) || (commUartTxMutexHandle == NULL))
  {
    return;
  }

  if (xSemaphoreTake(commUartTxMutexHandle, pdMS_TO_TICKS(20U)) == pdTRUE)
  {
    (void)HAL_UART_Transmit(&huart6, (uint8_t *)data, length, 100U);
    (void)xSemaphoreGive(commUartTxMutexHandle);
  }
}

static void StartTelemetryTask(void *argument)
{
  TelemetrySnapshot_t telemetry = {
    .uptime_ms = 0U,
    .depth_mm = 0,
    .roll_cdeg = 0,
    .pitch_cdeg = 0,
    .yaw_cdeg = 0,
    .status_flags = 0U,
    .last_command_sequence = 0U
  };
  ControlCommand_t latestCommand;
  uint8_t frame[COMM_TELEMETRY_FRAME_SIZE];
  uint8_t sequence = 0U;
  uint16_t frameLength;
  bool linkOk;
  bool failsafeActive;
  TickType_t lastWakeTime;

  (void)argument;

  /* Sensor fields remain zero and invalid until a sensor reader updates them. */
  if (!CommInterface_SetTelemetry(&telemetry, pdMS_TO_TICKS(10U)))
  {
    Error_Handler();
  }

  lastWakeTime = xTaskGetTickCount();

  for (;;)
  {
    vTaskDelayUntil(&lastWakeTime, pdMS_TO_TICKS(100U));

    if (!CommInterface_GetTelemetry(&telemetry, pdMS_TO_TICKS(10U)))
    {
      continue;
    }

    telemetry.uptime_ms = HAL_GetTick();
    if (CommInterface_GetCommand(&latestCommand, 0U))
    {
      telemetry.last_command_sequence = latestCommand.sequence;
    }

    telemetry.status_flags &=
        (uint16_t)~(COMM_STATUS_ARMED |
                    COMM_STATUS_COMMAND_LINK_OK |
                    COMM_STATUS_FAILSAFE_ACTIVE);

    if (CommInterface_GetSafetyState(&linkOk, &failsafeActive, 0U))
    {
      if (linkOk)
      {
        telemetry.status_flags |= COMM_STATUS_COMMAND_LINK_OK;
      }

      if (failsafeActive)
      {
        telemetry.status_flags |= COMM_STATUS_FAILSAFE_ACTIVE;
      }

#if APP_MOTOR_OUTPUTS_ENABLED
      if (linkOk && (!failsafeActive) &&
          ((latestCommand.control_flags & COMM_COMMAND_ARM_REQUEST) != 0U))
      {
        telemetry.status_flags |= COMM_STATUS_ARMED;
      }
#endif
    }

    frameLength = CommEncoder_BuildTelemetry(&telemetry, sequence, frame,
                                             sizeof(frame));
    if (frameLength == 0U)
    {
      continue;
    }

    if (xSemaphoreTake(commUartTxMutexHandle, pdMS_TO_TICKS(20U)) != pdTRUE)
    {
      continue;
    }

    /* Remove a stale completion token before starting a new transfer. */
    (void)xSemaphoreTake(commUartTxDoneSemaphoreHandle, 0U);

    if (HAL_UART_Transmit_IT(&huart6, frame, frameLength) == HAL_OK)
    {
      ++sequence;
      if (xSemaphoreTake(commUartTxDoneSemaphoreHandle,
                         pdMS_TO_TICKS(20U)) != pdTRUE)
      {
        (void)HAL_UART_AbortTransmit(&huart6);
      }
    }

    (void)xSemaphoreGive(commUartTxMutexHandle);
  }
}

static void StartControlSafetyTask(void *argument)
{
  ControlCommand_t activeCommand;
  MotorOutputs_t motorOutputs;
#if APP_SINGLE_MOTOR_TEST_ENABLED
  MotorTestRequest_t motorTestRequest;
  uint32_t motorTestEndMs = 0U;
#endif
  TickType_t lastWakeTime;
  bool linkOk;
  bool failsafeActive;
  bool commandSafe;
#if APP_SINGLE_MOTOR_TEST_ENABLED
  bool motorTestActive = false;
#endif

  (void)argument;
  Movement_SetNeutral(&motorOutputs);

#if APP_MOTOR_OUTPUTS_ENABLED || APP_MOTOR_NEUTRAL_TEST
  /* ESCs see neutral only during their startup/arming interval. */
  if (!Movement_StartPwmNeutral())
  {
    Error_Handler();
  }
  osDelay(3000U);
#endif

  lastWakeTime = xTaskGetTickCount();

  for (;;)
  {
    commandSafe = false;

    if (CommInterface_UpdateCommandSafety(HAL_GetTick(),
                                          COMMAND_LINK_TIMEOUT_MS,
                                          pdMS_TO_TICKS(10U)) &&
        CommInterface_GetSafetyState(&linkOk, &failsafeActive,
                                     pdMS_TO_TICKS(10U)) &&
        CommInterface_GetCommand(&activeCommand, pdMS_TO_TICKS(10U)) &&
        Movement_Compute(&activeCommand, &motorOutputs))
    {
      commandSafe = linkOk && (!failsafeActive);
    }

    if (!commandSafe)
    {
      Movement_SetNeutral(&motorOutputs);
    }

#if APP_MOTOR_OUTPUTS_ENABLED
    /* A validation-build hardware boundary: never exceed the configured
       low-power PWM delta even if a valid packet requests full thrust. */
    Movement_LimitPwmDelta(&motorOutputs, APP_MOTOR_OUTPUT_LIMIT_US);
    Movement_Apply(&motorOutputs);
#elif APP_MOTOR_NEUTRAL_TEST
    /* Binary motion commands remain blocked in hardware validation mode. */
    Movement_SetNeutral(&motorOutputs);

#if APP_SINGLE_MOTOR_TEST_ENABLED
    if (motorTestActive &&
        ((int32_t)(HAL_GetTick() - motorTestEndMs) >= 0))
    {
      motorTestActive = false;
    }

    if ((!motorTestActive) &&
        (xQueueReceive(motorTestQueueHandle, &motorTestRequest, 0U) == pdPASS))
    {
      motorTestActive = true;
      motorTestEndMs = HAL_GetTick() + SINGLE_MOTOR_TEST_DURATION_MS;
    }

    if (motorTestActive)
    {
      (void)Movement_SetSingleMotorTest(&motorOutputs,
                                        motorTestRequest.motor_index,
                                        motorTestRequest.direction);
    }
#endif

    Movement_Apply(&motorOutputs);
#else
    (void)motorOutputs;
#endif

    vTaskDelayUntil(&lastWakeTime,
                    pdMS_TO_TICKS(CONTROL_SAFETY_PERIOD_MS));
  }
}

static void StartSensorTask(void *argument)
{
  TelemetrySnapshot_t telemetry;
  uint32_t nowMs;
  uint32_t lastImuStartMs = 0U;
  uint32_t lastImuDataMs = 0U;
  uint32_t lastMagReadMs = 0U;
  uint32_t lastMagDataMs = 0U;
  uint32_t lastDepthDataMs = 0U;
  uint32_t lastImuRetryMs;
  uint32_t lastMagRetryMs;
  uint32_t lastDepthRetryMs;
  uint16_t surfaceSampleCount = 0U;
  uint8_t imuAddress = MPU6050_ADDR;
  bool imuDetected = false;
  bool magDetected = false;
  bool depthDetected = false;
  bool imuInitialized = false;
  bool magInitialized = false;
  bool depthInitialized = false;
  bool imuValid = false;
  bool magValid = false;
  bool depthValid = false;
  HAL_StatusTypeDef magReadStatus;
  float surfacePressureSum = 0.0f;
  float surfacePressureMbar = 0.0f;
  float pressureMbar;
  float temperatureC;
  TickType_t lastWakeTime;

  (void)argument;

  /* Let power and the shared telemetry snapshot settle before sensor reset. */
  osDelay(100U);
  nowMs = HAL_GetTick();
  lastImuRetryMs = nowMs - SENSOR_RETRY_PERIOD_MS;
  lastMagRetryMs = nowMs - SENSOR_RETRY_PERIOD_MS;
  lastDepthRetryMs = nowMs - SENSOR_RETRY_PERIOD_MS;
  lastWakeTime = xTaskGetTickCount();

  for (;;)
  {
    nowMs = HAL_GetTick();

    /* Detect and initialize the IMU. AD0 selects either 0x68 or 0x69. */
    if ((!imuInitialized) &&
        ((nowMs - lastImuRetryMs) >= SENSOR_RETRY_PERIOD_MS))
    {
      lastImuRetryMs = nowMs;
      imuDetected = false;

      if (HAL_I2C_IsDeviceReady(&hi2c1, MPU6050_ADDR, 2U, 20U) == HAL_OK)
      {
        imuAddress = MPU6050_ADDR;
        imuDetected = true;
      }
      else if (HAL_I2C_IsDeviceReady(&hi2c1, MPU6050_ADDR_ALT,
                                     2U, 20U) == HAL_OK)
      {
        imuAddress = MPU6050_ADDR_ALT;
        imuDetected = true;
      }

      if (imuDetected &&
          (MPU6050_Init(&mpu6050, &hi2c1, imuAddress) == HAL_OK))
      {
        imuInitialized = true;
        imuValid = false;
        lastImuStartMs = nowMs - IMU_SAMPLE_PERIOD_MS;
        lastImuDataMs = nowMs;
      }
    }

    /* Process a completed MPU6050 DMA sample before sharing I2C1. */
    if (imuInitialized)
    {
      if (mpu6050.data_ready != 0U)
      {
        MPU6050_ProcessData(&mpu6050);

        if ((mpu6050.roll >= -180.0f) && (mpu6050.roll <= 180.0f) &&
            (mpu6050.pitch >= -90.0f) && (mpu6050.pitch <= 90.0f))
        {
          imuValid = true;
          lastImuDataMs = nowMs;
        }
      }

      if ((nowMs - lastImuDataMs) > IMU_STALE_TIMEOUT_MS)
      {
        imuValid = false;
      }
    }

    /* The HW-290 magnetometer is exposed on I2C1 through MPU6050 bypass. */
    if (imuInitialized && (!magInitialized) &&
        ((nowMs - lastMagRetryMs) >= SENSOR_RETRY_PERIOD_MS) &&
        (HAL_I2C_GetState(&hi2c1) == HAL_I2C_STATE_READY))
    {
      lastMagRetryMs = nowMs;
      magDetected =
          (HAL_I2C_IsDeviceReady(&hi2c1, HW290_QMC5883L_ADDR,
                                 2U, 20U) == HAL_OK) ||
          (HAL_I2C_IsDeviceReady(&hi2c1, HW290_HMC5883L_ADDR,
                                 2U, 20U) == HAL_OK);

      if (magDetected &&
          (HW290_Magnetometer_Init(&hw290Magnetometer, &hi2c1) == HAL_OK))
      {
        magInitialized = true;
        magValid = false;
        lastMagReadMs = nowMs - MAG_SAMPLE_PERIOD_MS;
        lastMagDataMs = nowMs;
      }
    }

    if (magInitialized &&
        ((nowMs - lastMagReadMs) >= MAG_SAMPLE_PERIOD_MS) &&
        (HAL_I2C_GetState(&hi2c1) == HAL_I2C_STATE_READY))
    {
      lastMagReadMs = nowMs;
      magReadStatus = HW290_Magnetometer_Read(&hw290Magnetometer);

      if (magReadStatus == HAL_OK)
      {
        (void)HW290_Magnetometer_ComputeYaw(&hw290Magnetometer,
                                            mpu6050.roll,
                                            mpu6050.pitch);
        magValid = true;
        lastMagDataMs = nowMs;
      }
    }

    if (magInitialized &&
        ((nowMs - lastMagDataMs) > MAG_STALE_TIMEOUT_MS))
    {
      magValid = false;
    }

    /* Start MPU DMA last so no blocking magnetometer access overlaps it. */
    if (imuInitialized &&
        ((nowMs - lastImuStartMs) >= IMU_SAMPLE_PERIOD_MS) &&
        (HAL_I2C_GetState(&hi2c1) == HAL_I2C_STATE_READY) &&
        (MPU6050_ReadAll_DMA(&mpu6050) == HAL_OK))
    {
      lastImuStartMs = nowMs;
    }

    /* Detect, reset and load factory calibration from the depth sensor. */
    if ((!depthInitialized) &&
        ((nowMs - lastDepthRetryMs) >= SENSOR_RETRY_PERIOD_MS))
    {
      lastDepthRetryMs = nowMs;
      depthDetected =
          (HAL_I2C_IsDeviceReady(&hi2c3, MS5837_ADDR, 2U, 20U) == HAL_OK);

      if (depthDetected &&
          (MS5837_Init(&depth_sensor, &hi2c3, MS5837_OSR_4096) == MS5837_OK))
      {
        depthInitialized = true;
        depthValid = false;
        surfaceSampleCount = 0U;
        surfacePressureSum = 0.0f;
        surfacePressureMbar = 0.0f;
        lastDepthDataMs = nowMs;
        (void)MS5837_StartReading(&depth_sensor);
      }
    }

    if (depthInitialized)
    {
      MS5837_Process(&depth_sensor);

      if (MS5837_IsDataReady(&depth_sensor))
      {
        pressureMbar = MS5837_GetPressure(&depth_sensor);
        temperatureC = MS5837_GetTemperature(&depth_sensor);
        depth_sensor.data_ready = false;

        /* Reject impossible compensation results before publishing them. */
        if ((pressureMbar > 100.0f) && (pressureMbar < 35000.0f) &&
            (temperatureC > -40.0f) && (temperatureC < 100.0f))
        {
          lastDepthDataMs = nowMs;

          /* The first twenty samples define zero depth at startup. */
          if (surfaceSampleCount < DEPTH_SURFACE_SAMPLE_COUNT)
          {
            surfacePressureSum += pressureMbar;
            ++surfaceSampleCount;
            depth_sensor.depth = 0.0f;

            if (surfaceSampleCount == DEPTH_SURFACE_SAMPLE_COUNT)
            {
              surfacePressureMbar =
                  surfacePressureSum / (float)DEPTH_SURFACE_SAMPLE_COUNT;
              depthValid = true;
            }
          }
          else
          {
            /* mbar -> Pa, then hydrostatic pressure -> metres of fresh water. */
            depth_sensor.depth =
                ((pressureMbar - surfacePressureMbar) * 100.0f) /
                (WATER_DENSITY_KG_M3 * STANDARD_GRAVITY_M_S2);
            depthValid = true;
          }
        }
        else
        {
          depthValid = false;
        }
      }

      if (MS5837_GetState(&depth_sensor) == MS5837_STATE_IDLE)
      {
        (void)MS5837_StartReading(&depth_sensor);
      }

      if ((nowMs - lastDepthDataMs) > DEPTH_STALE_TIMEOUT_MS)
      {
        depthValid = false;
      }
    }

    if (CommInterface_GetTelemetry(&telemetry, pdMS_TO_TICKS(10U)))
    {
      telemetry.status_flags &=
          (uint16_t)~(COMM_STATUS_IMU_DETECTED |
                      COMM_STATUS_DEPTH_SENSOR_DETECTED |
                      COMM_STATUS_MAGNETOMETER_DETECTED |
                      COMM_STATUS_SENSOR_FAULT |
                      COMM_STATUS_DEPTH_VALID |
                      COMM_STATUS_ATTITUDE_VALID |
                      COMM_STATUS_YAW_VALID);

      if (imuDetected)
      {
        telemetry.status_flags |= COMM_STATUS_IMU_DETECTED;
      }

      if (depthDetected)
      {
        telemetry.status_flags |= COMM_STATUS_DEPTH_SENSOR_DETECTED;
      }

      if (magDetected)
      {
        telemetry.status_flags |= COMM_STATUS_MAGNETOMETER_DETECTED;
      }

      if (imuValid)
      {
        telemetry.roll_cdeg = Sensor_DegreesToCentidegrees(mpu6050.roll);
        telemetry.pitch_cdeg = Sensor_DegreesToCentidegrees(mpu6050.pitch);
        telemetry.status_flags |= COMM_STATUS_ATTITUDE_VALID;
      }
      else
      {
        telemetry.roll_cdeg = 0;
        telemetry.pitch_cdeg = 0;
      }

      if (imuValid && magValid)
      {
        telemetry.yaw_cdeg =
            Sensor_DegreesToCentidegrees(hw290Magnetometer.yaw_deg);
        telemetry.status_flags |= COMM_STATUS_YAW_VALID;
      }
      else
      {
        telemetry.yaw_cdeg = 0;
      }

      if (depthValid)
      {
        telemetry.depth_mm =
            Sensor_MetresToMillimetres(depth_sensor.depth);
        telemetry.status_flags |= COMM_STATUS_DEPTH_VALID;
      }
      else
      {
        telemetry.depth_mm = 0;
      }

      if ((!imuInitialized) || (!magInitialized) || (!depthInitialized) ||
          (imuInitialized &&
           ((nowMs - lastImuDataMs) > SENSOR_FAULT_TIMEOUT_MS)) ||
          (magInitialized &&
           ((nowMs - lastMagDataMs) > SENSOR_FAULT_TIMEOUT_MS)) ||
          (depthInitialized &&
           ((nowMs - lastDepthDataMs) > SENSOR_FAULT_TIMEOUT_MS)))
      {
        telemetry.status_flags |= COMM_STATUS_SENSOR_FAULT;
      }

      (void)CommInterface_SetTelemetry(&telemetry, pdMS_TO_TICKS(10U));
    }

    vTaskDelayUntil(&lastWakeTime, pdMS_TO_TICKS(SENSOR_TASK_PERIOD_MS));
  }
}

static int16_t Sensor_DegreesToCentidegrees(float degrees)
{
  float scaled = degrees * 100.0f;

  if (scaled > 32767.0f)
  {
    return 32767;
  }
  if (scaled < -32768.0f)
  {
    return -32768;
  }

  scaled += (scaled >= 0.0f) ? 0.5f : -0.5f;
  return (int16_t)scaled;
}

static int32_t Sensor_MetresToMillimetres(float metres)
{
  float scaled = metres * 1000.0f;
  scaled += (scaled >= 0.0f) ? 0.5f : -0.5f;
  return (int32_t)scaled;
}

void CommTest_UART_RxCpltCallback(void)
{
  BaseType_t higherPriorityTaskWoken = pdFALSE;
  uint8_t receivedByte = commUartRxByte;

  if (commUartRxQueueHandle != NULL)
  {
    (void)xQueueSendFromISR(commUartRxQueueHandle, &receivedByte,
                            &higherPriorityTaskWoken);
  }

  (void)HAL_UART_Receive_IT(&huart6, &commUartRxByte, 1U);
  portYIELD_FROM_ISR(higherPriorityTaskWoken);
}

void CommTest_UART_TxCpltCallback(void)
{
  BaseType_t higherPriorityTaskWoken = pdFALSE;

  if (commUartTxDoneSemaphoreHandle != NULL)
  {
    (void)xSemaphoreGiveFromISR(commUartTxDoneSemaphoreHandle,
                                &higherPriorityTaskWoken);
  }

  portYIELD_FROM_ISR(higherPriorityTaskWoken);
}

/* USER CODE END Application */
